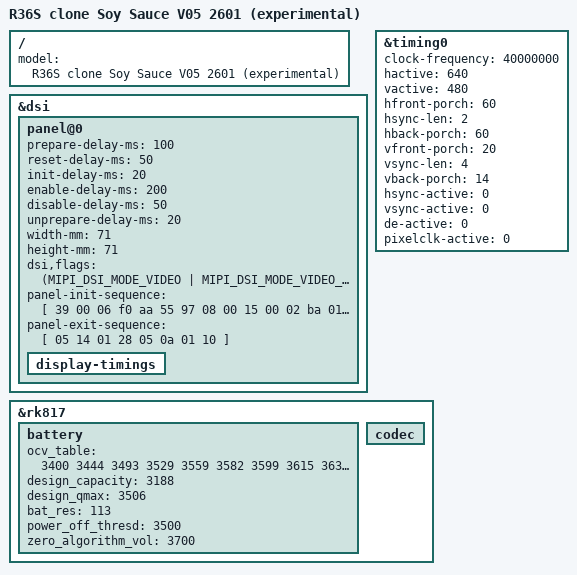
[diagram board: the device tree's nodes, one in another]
// SPDX-License-Identifier: (GPL-2.0+ OR MIT)
/*
 * EXPERIMENTAL - not tested on hardware by andr36oid. Keep a copy of the
 * files you replace so you can go back.
 *
 * Soy Sauce Y3506_V05_20251215 batch 2601 (51-command panel).
 * Source: dArkOSRE port by southoz (dArkOSRE-R36, soysauce/Y3506_V05_20251215 2601).
 */

/dts-v1/;
#include "rk3326-r36s-clone-soysauce.dtsi"

/ {
	model = "R36S clone Soy Sauce V05 2601 (experimental)";
};

&dsi {
	panel@0 {
		prepare-delay-ms = <100>;
		reset-delay-ms = <50>;
		init-delay-ms = <20>;
		enable-delay-ms = <200>;
		disable-delay-ms = <50>;
		unprepare-delay-ms = <20>;
		width-mm = <71>;
		height-mm = <71>;
		dsi,flags = <(MIPI_DSI_MODE_VIDEO |
		      MIPI_DSI_MODE_VIDEO_BURST |
		      MIPI_DSI_MODE_EOT_PACKET |
		      MIPI_DSI_MODE_LPM)>;
		panel-init-sequence = [
			39 00 06 f0 aa 55 97 08 00
			15 00 02 ba 01
			15 00 02 a1 ff
			15 00 02 a0 cc
			15 00 02 a4 ff
			15 00 02 a5 0b
			15 00 02 93 7a
			15 00 02 b6 02
			15 00 02 9d aa
			15 00 02 e4 95
			39 00 06 f0 aa 55 97 08 01
			15 00 02 60 06
			15 00 02 62 c8
			15 00 02 63 62
			15 00 02 65 80
			15 00 02 66 89
			15 00 02 68 91
			15 00 02 69 c3
			15 00 02 60 ff
			15 00 02 61 ff
			15 00 02 62 ff
			15 00 02 63 ff
			15 00 02 64 ff
			15 00 02 65 ff
			15 00 02 66 ff
			15 00 02 67 ff
			15 00 02 68 ff
			15 00 02 69 ff
			39 00 03 e3 5a 87
			15 00 02 cf 2d
			15 00 02 e9 51
			39 00 2d b3 3f 34 34 34 28 29 09 0b 0d 0f 01 3f 34 34 3f 3f 3f 3f 3f 3f 3f 3f 3f 34 34 34 28 29 08 0a 0c 0e 00 3f 34 34 3f 3f 3f 3f 3f 3f 3f 3f
			39 00 09 a0 18 05 52 52 18 04 52 52
			39 00 06 a7 11 52 52 52 52
			39 00 0d a8 00 03 01 fb 00 00 04 01 fc 03 03 00
			39 00 0d a9 08 03 01 f5 00 08 02 01 f5 03 03 00
			39 00 0d aa 08 01 01 f7 00 08 00 01 f8 03 03 00
			39 00 0d ab 00 01 01 f9 00 00 02 01 fa 03 03 00
			39 00 08 a4 00 08 0f 08 0a 00 00
			39 00 09 a6 11 ff 88 06 11 ff 88 06
			39 00 08 b0 22 22 22 22 22 22 f4
			15 00 02 b7 27
			39 00 14 f1 7f 6d 61 56 57 48 4c 35 4c 49 48 64 4f 57 4b 45 38 26 00
			39 00 14 f2 7f 6d 61 56 57 48 4c 35 4c 49 48 64 4f 57 4b 45 38 26 00
			39 00 06 e7 10 02 7f 00 00
			15 00 02 ed 02
			15 00 02 ee 22
			39 00 03 e6 e8 35
			15 00 02 35 00
			05 96 01 11
			05 32 01 29
		];
		panel-exit-sequence = [
			05 14 01 28
			05 0a 01 10
		];
		display-timings {
			/* one mode only: the R36S alternates below do not fit this panel */
			/delete-node/ timing1;
			/delete-node/ timing2;
		};
	};
};

&timing0 {
	clock-frequency = <40000000>;
	hactive = <640>;
	vactive = <480>;
	hfront-porch = <60>;
	hsync-len = <2>;
	hback-porch = <60>;
	vfront-porch = <20>;
	vsync-len = <4>;
	vback-porch = <14>;
	hsync-active = <0>;
	vsync-active = <0>;
	de-active = <0>;
	pixelclk-active = <0>;
};

&rk817 {
	battery {
		/*
		 * Stock values of the V05 batch 2601 (its U-Boot DTB; southoz's
		 * dArkOSRE port agrees).
		 */
		ocv_table = <3400 3444 3493 3529 3559 3582 3599
			3615 3634 3660 3701 3759 3809 3852
			3886 3911 3961 4012 4028 4075 4182>;
		design_capacity = <3188>;
		design_qmax = <3506>;
		bat_res = <113>;
		power_off_thresd = <3500>;
		zero_algorithm_vol = <3700>;
	};
};

/* no speaker switch in the V05 port */
&rk817 {
	codec {
		/delete-property/ spk-ctl-gpios;
	};
};
